# N32H7xx register map
Vendor: Nationstech Ltd.; File version: 1.0
CPU: CM7 r1p1, little endian, MPU, FPU, 4 interrupt priority bits
Registers are 32-bit, read-write, reset 0x0 unless marked. A register's access mark holds for its fields unless they carry their own. Offsets are from the block's base; [hi:lo] are bit positions.

## DAC12
Base 0x4000FC00
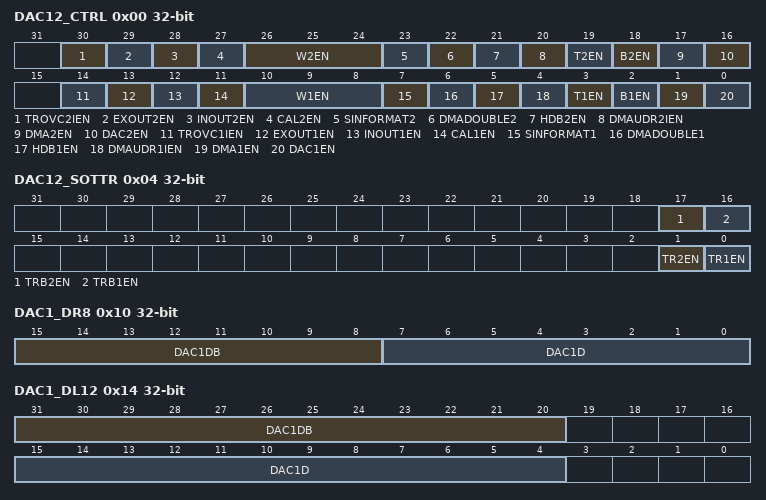
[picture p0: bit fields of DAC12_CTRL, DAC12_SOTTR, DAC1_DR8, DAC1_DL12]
0x00 DAC12_CTRL
  [30] TROVC2IEN, [29] EXOUT2EN, [28] INOUT2EN, [27] CAL2EN, [26:24] W2EN, [23] SINFORMAT2, [22] DMADOUBLE2, [21] HDB2EN, [20] DMAUDR2IEN, [19] T2EN, [18] B2EN, [17] DMA2EN, [16] DAC2EN, [14] TROVC1IEN, [13] EXOUT1EN, [12] INOUT1EN, [11] CAL1EN, [10:8] W1EN, [7] SINFORMAT1, [6] DMADOUBLE1, [5] HDB1EN, [4] DMAUDR1IEN, [3] T1EN, [2] B1EN, [1] DMA1EN, [0] DAC1EN
0x04 DAC12_SOTTR wo
  [17] TRB2EN, [16] TRB1EN, [1] TR2EN, [0] TR1EN
0x08 DAC1_DATO ro
  [11:0] DAC1DO
0x0C DAC2_DATO ro
  [11:0] DAC2DO
0x10 DAC1_DR8
  [15:8] DAC1DB, [7:0] DAC1D
0x14 DAC1_DL12
  [31:20] DAC1DB, [15:4] DAC1D
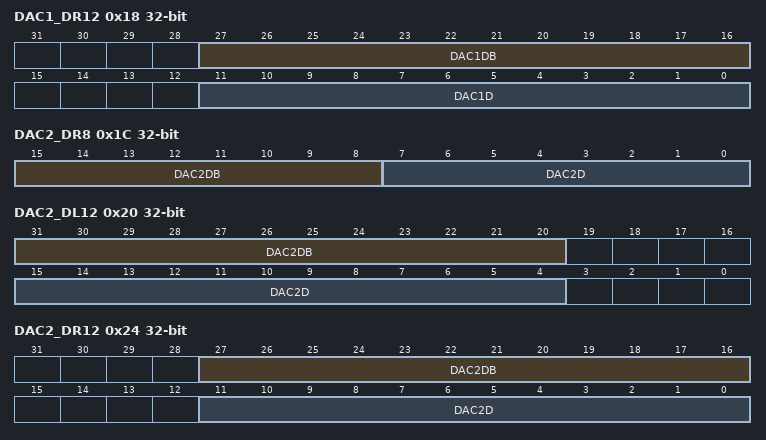
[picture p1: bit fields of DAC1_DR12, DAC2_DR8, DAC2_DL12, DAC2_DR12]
0x18 DAC1_DR12
  [27:16] DAC1DB, [11:0] DAC1D
0x1C DAC2_DR8
  [15:8] DAC2DB, [7:0] DAC2D
0x20 DAC2_DL12
  [31:20] DAC2DB, [15:4] DAC2D
0x24 DAC2_DR12
  [27:16] DAC2DB, [11:0] DAC2D
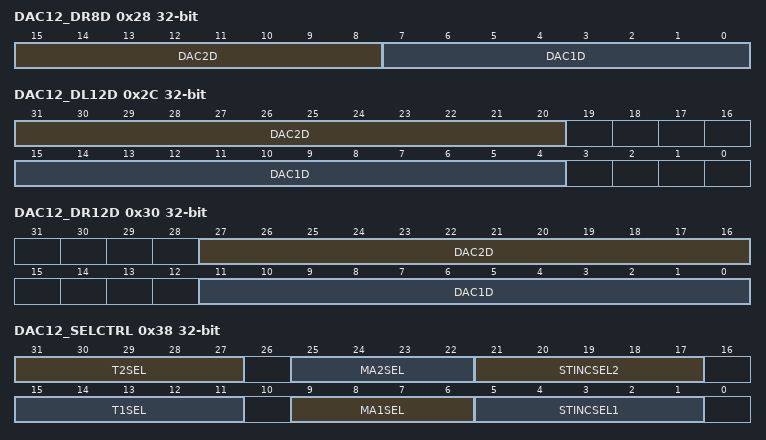
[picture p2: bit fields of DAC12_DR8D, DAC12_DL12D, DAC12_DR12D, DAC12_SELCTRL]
0x28 DAC12_DR8D
  [15:8] DAC2D, [7:0] DAC1D
0x2C DAC12_DL12D
  [31:20] DAC2D, [15:4] DAC1D
0x30 DAC12_DR12D
  [27:16] DAC2D, [11:0] DAC1D
0x38 DAC12_SELCTRL
  [31:27] T2SEL, [25:22] MA2SEL, [21:17] STINCSEL2, [15:11] T1SEL, [9:6] MA1SEL, [5:1] STINCSEL1
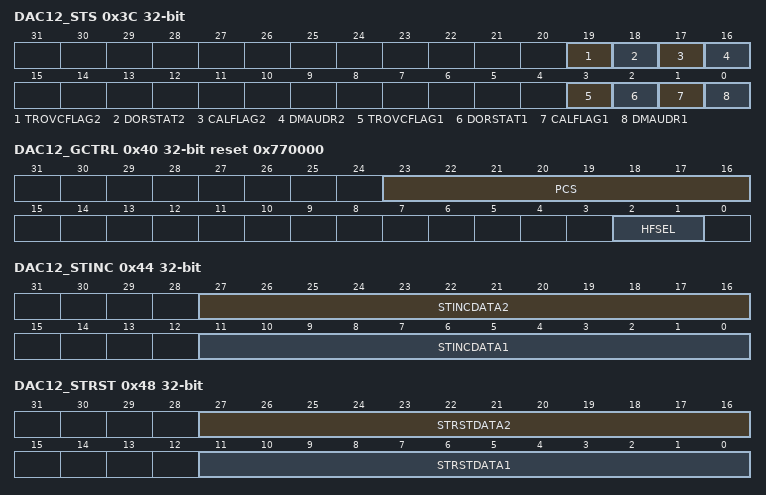
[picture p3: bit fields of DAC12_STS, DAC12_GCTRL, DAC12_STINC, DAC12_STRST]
0x3C DAC12_STS
  [19] TROVCFLAG2, [18] DORSTAT2 ro, [17] CALFLAG2 ro, [16] DMAUDR2, [3] TROVCFLAG1, [2] DORSTAT1 ro, [1] CALFLAG1 ro, [0] DMAUDR1
0x40 DAC12_GCTRL reset 0x770000
  [23:16] PCS, [2:1] HFSEL
0x44 DAC12_STINC
  [27:16] STINCDATA2, [11:0] STINCDATA1
0x48 DAC12_STRST
  [27:16] STRSTDATA2, [11:0] STRSTDATA1
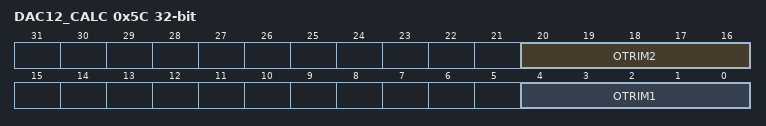
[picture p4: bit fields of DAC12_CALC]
0x5C DAC12_CALC
  [20:16] OTRIM2, [4:0] OTRIM1

## DAC34
Base 0x400F1800
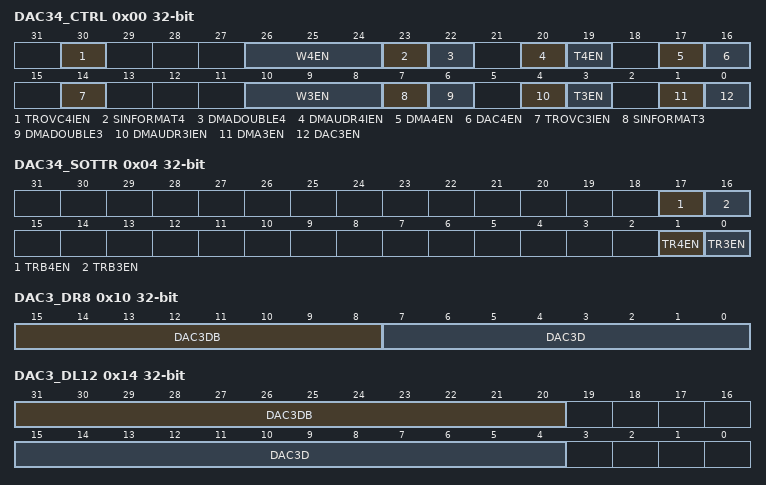
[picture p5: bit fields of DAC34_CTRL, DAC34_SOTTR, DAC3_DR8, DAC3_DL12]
0x00 DAC34_CTRL
  [30] TROVC4IEN, [26:24] W4EN, [23] SINFORMAT4, [22] DMADOUBLE4, [20] DMAUDR4IEN, [19] T4EN, [17] DMA4EN, [16] DAC4EN, [14] TROVC3IEN, [10:8] W3EN, [7] SINFORMAT3, [6] DMADOUBLE3, [4] DMAUDR3IEN, [3] T3EN, [1] DMA3EN, [0] DAC3EN
0x04 DAC34_SOTTR wo
  [17] TRB4EN, [16] TRB3EN, [1] TR4EN, [0] TR3EN
0x08 DAC3_DATO ro
  [11:0] DAC3DO
0x0C DAC4_DATO ro
  [11:0] DAC4DO
0x10 DAC3_DR8
  [15:8] DAC3DB, [7:0] DAC3D
0x14 DAC3_DL12
  [31:20] DAC3DB, [15:4] DAC3D
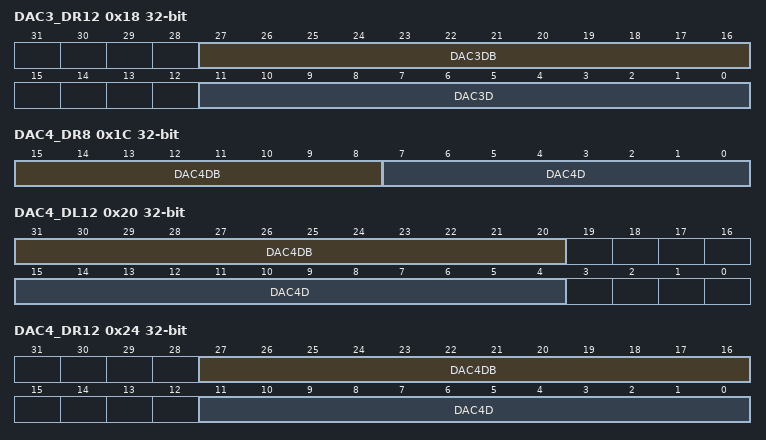
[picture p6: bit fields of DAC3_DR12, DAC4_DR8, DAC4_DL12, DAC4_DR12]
0x18 DAC3_DR12
  [27:16] DAC3DB, [11:0] DAC3D
0x1C DAC4_DR8
  [15:8] DAC4DB, [7:0] DAC4D
0x20 DAC4_DL12
  [31:20] DAC4DB, [15:4] DAC4D
0x24 DAC4_DR12
  [27:16] DAC4DB, [11:0] DAC4D
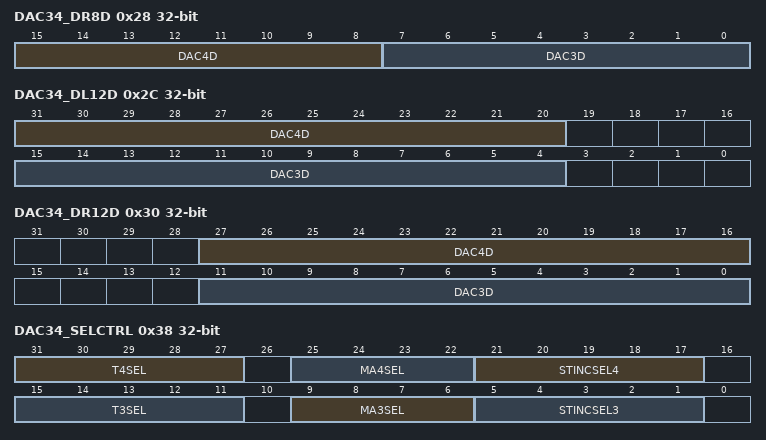
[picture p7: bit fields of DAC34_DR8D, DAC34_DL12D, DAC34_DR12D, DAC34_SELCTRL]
0x28 DAC34_DR8D
  [15:8] DAC4D, [7:0] DAC3D
0x2C DAC34_DL12D
  [31:20] DAC4D, [15:4] DAC3D
0x30 DAC34_DR12D
  [27:16] DAC4D, [11:0] DAC3D
0x38 DAC34_SELCTRL
  [31:27] T4SEL, [25:22] MA4SEL, [21:17] STINCSEL4, [15:11] T3SEL, [9:6] MA3SEL, [5:1] STINCSEL3
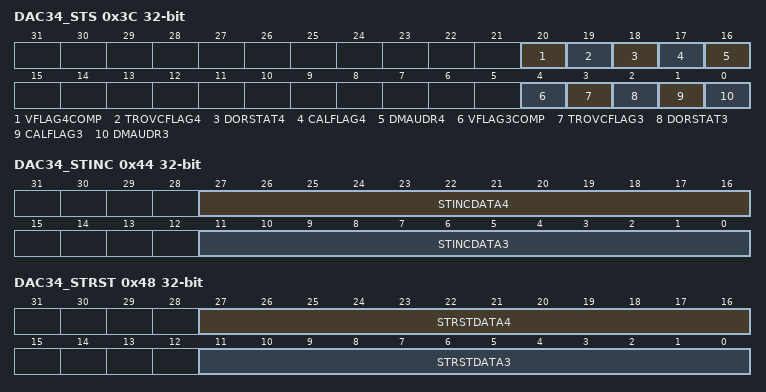
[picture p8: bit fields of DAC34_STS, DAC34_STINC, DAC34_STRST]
0x3C DAC34_STS
  [20] VFLAG4COMP ro, [19] TROVCFLAG4, [18] DORSTAT4 ro, [17] CALFLAG4 ro, [16] DMAUDR4, [4] VFLAG3COMP ro, [3] TROVCFLAG3, [2] DORSTAT3 ro, [1] CALFLAG3 ro, [0] DMAUDR3
0x40 DAC34_GCTRL reset 0x770000
  [20:16] PCS
0x44 DAC34_STINC
  [27:16] STINCDATA4, [11:0] STINCDATA3
0x48 DAC34_STRST
  [27:16] STRSTDATA4, [11:0] STRSTDATA3

## DAC56
Base 0x400F1C00
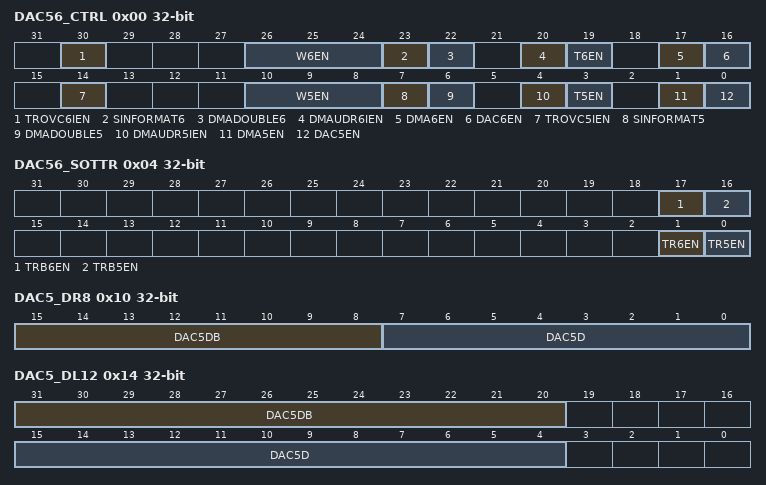
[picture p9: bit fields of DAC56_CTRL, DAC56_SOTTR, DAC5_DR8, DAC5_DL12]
0x00 DAC56_CTRL
  [30] TROVC6IEN, [26:24] W6EN, [23] SINFORMAT6, [22] DMADOUBLE6, [20] DMAUDR6IEN, [19] T6EN, [17] DMA6EN, [16] DAC6EN, [14] TROVC5IEN, [10:8] W5EN, [7] SINFORMAT5, [6] DMADOUBLE5, [4] DMAUDR5IEN, [3] T5EN, [1] DMA5EN, [0] DAC5EN
0x04 DAC56_SOTTR wo
  [17] TRB6EN, [16] TRB5EN, [1] TR6EN, [0] TR5EN
0x08 DAC5_DATO ro
  [11:0] DAC5DO
0x0C DAC6_DATO ro
  [11:0] DAC6DO
0x10 DAC5_DR8
  [15:8] DAC5DB, [7:0] DAC5D
0x14 DAC5_DL12
  [31:20] DAC5DB, [15:4] DAC5D
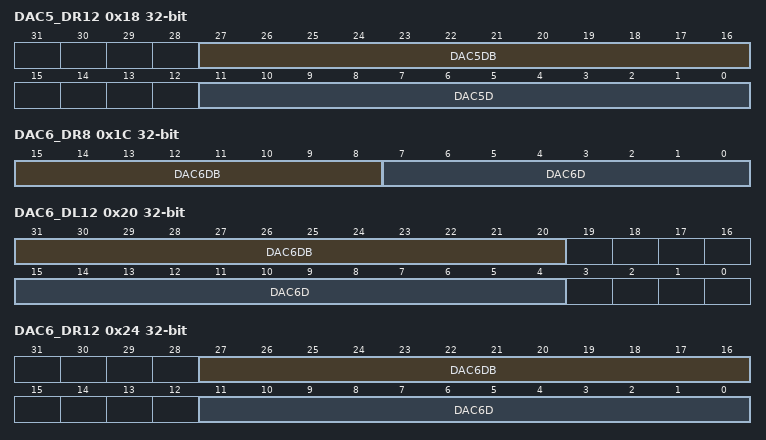
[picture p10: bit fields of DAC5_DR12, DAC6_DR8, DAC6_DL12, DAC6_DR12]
0x18 DAC5_DR12
  [27:16] DAC5DB, [11:0] DAC5D
0x1C DAC6_DR8
  [15:8] DAC6DB, [7:0] DAC6D
0x20 DAC6_DL12
  [31:20] DAC6DB, [15:4] DAC6D
0x24 DAC6_DR12
  [27:16] DAC6DB, [11:0] DAC6D
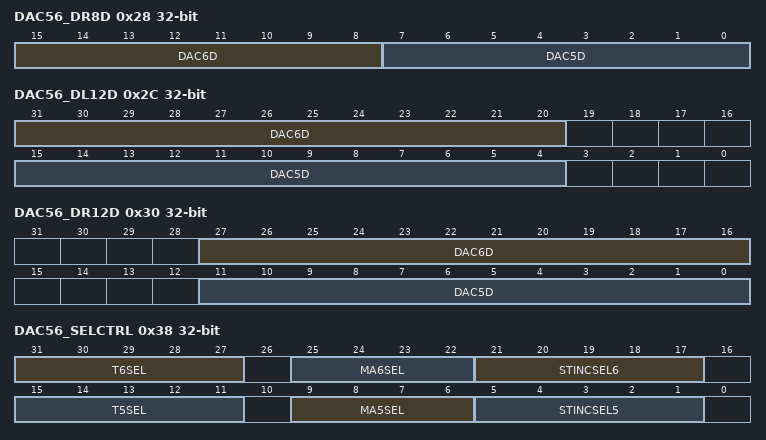
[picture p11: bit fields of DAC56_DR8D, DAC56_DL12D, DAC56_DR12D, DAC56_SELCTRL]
0x28 DAC56_DR8D
  [15:8] DAC6D, [7:0] DAC5D
0x2C DAC56_DL12D
  [31:20] DAC6D, [15:4] DAC5D
0x30 DAC56_DR12D
  [27:16] DAC6D, [11:0] DAC5D
0x38 DAC56_SELCTRL
  [31:27] T6SEL, [25:22] MA6SEL, [21:17] STINCSEL6, [15:11] T5SEL, [9:6] MA5SEL, [5:1] STINCSEL5
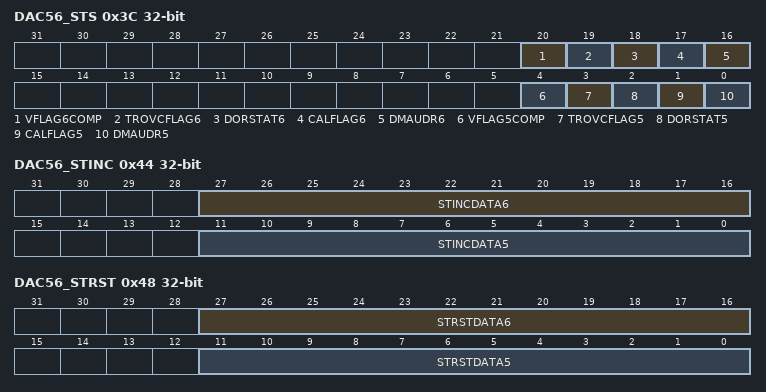
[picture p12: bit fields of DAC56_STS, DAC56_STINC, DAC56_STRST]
0x3C DAC56_STS
  [20] VFLAG6COMP ro, [19] TROVCFLAG6, [18] DORSTAT6 ro, [17] CALFLAG6 ro, [16] DMAUDR6, [4] VFLAG5COMP ro, [3] TROVCFLAG5, [2] DORSTAT5 ro, [1] CALFLAG5 ro, [0] DMAUDR5
0x40 DAC56_GCTRL reset 0x770000
  [20:16] PCS
0x44 DAC56_STINC
  [27:16] STINCDATA6, [11:0] STINCDATA5
0x48 DAC56_STRST
  [27:16] STRSTDATA6, [11:0] STRSTDATA5
